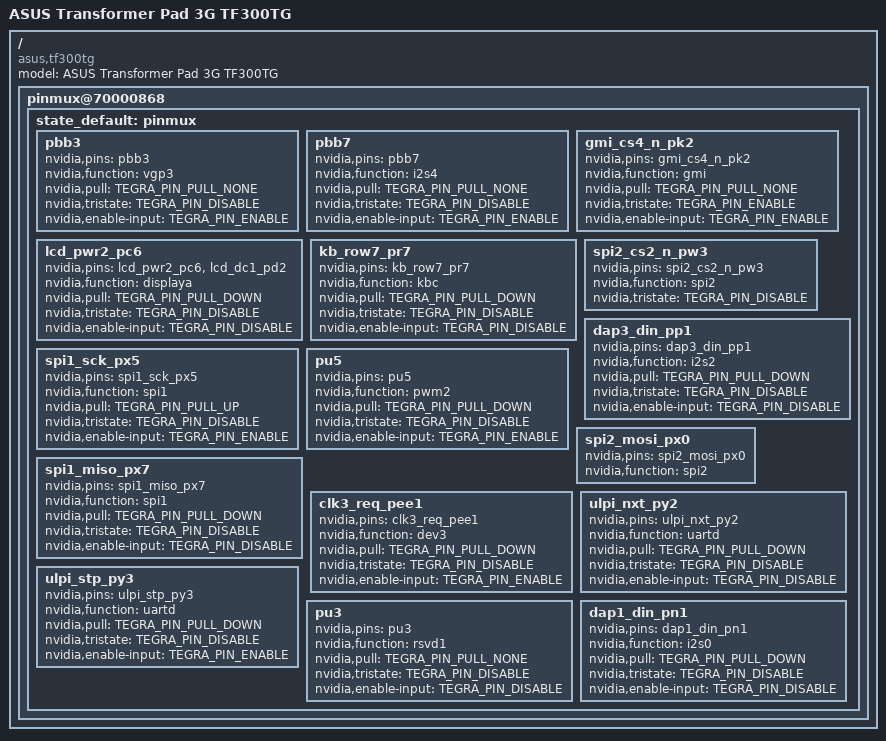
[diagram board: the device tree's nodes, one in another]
// SPDX-License-Identifier: GPL-2.0
/dts-v1/;

#include "tegra30-asus-transformer.dtsi"

/ {
	model = "ASUS Transformer Pad 3G TF300TG";
	compatible = "asus,tf300tg", "nvidia,tegra30";

	pinmux@70000868 {
		state_default: pinmux {
			pbb3 {
				nvidia,pins = "pbb3";
				nvidia,function = "vgp3";
				nvidia,pull = <TEGRA_PIN_PULL_NONE>;
				nvidia,tristate = <TEGRA_PIN_DISABLE>;
				nvidia,enable-input = <TEGRA_PIN_ENABLE>;
			};

			pbb7 {
				nvidia,pins = "pbb7";
				nvidia,function = "i2s4";
				nvidia,pull = <TEGRA_PIN_PULL_NONE>;
				nvidia,tristate = <TEGRA_PIN_DISABLE>;
				nvidia,enable-input = <TEGRA_PIN_ENABLE>;
			};

			gmi_cs4_n_pk2 {
				nvidia,pins = "gmi_cs4_n_pk2";
				nvidia,function = "gmi";
				nvidia,pull = <TEGRA_PIN_PULL_NONE>;
				nvidia,tristate = <TEGRA_PIN_ENABLE>;
				nvidia,enable-input = <TEGRA_PIN_ENABLE>;
			};

			lcd_pwr2_pc6 {
				nvidia,pins = "lcd_pwr2_pc6",
						"lcd_dc1_pd2";
				nvidia,function = "displaya";
				nvidia,pull = <TEGRA_PIN_PULL_DOWN>;
				nvidia,tristate = <TEGRA_PIN_DISABLE>;
				nvidia,enable-input = <TEGRA_PIN_DISABLE>;
			};

			kb_row7_pr7 {
				nvidia,pins = "kb_row7_pr7";
				nvidia,function = "kbc";
				nvidia,pull = <TEGRA_PIN_PULL_DOWN>;
				nvidia,tristate = <TEGRA_PIN_DISABLE>;
				nvidia,enable-input = <TEGRA_PIN_DISABLE>;
			};

			spi2_cs2_n_pw3 {
				nvidia,pins = "spi2_cs2_n_pw3";
				nvidia,function = "spi2";
				nvidia,tristate = <TEGRA_PIN_DISABLE>;
			};

			dap3_din_pp1 {
				nvidia,pins = "dap3_din_pp1";
				nvidia,function = "i2s2";
				nvidia,pull = <TEGRA_PIN_PULL_DOWN>;
				nvidia,tristate = <TEGRA_PIN_DISABLE>;
				nvidia,enable-input = <TEGRA_PIN_DISABLE>;
			};

			spi1_sck_px5 {
				nvidia,pins = "spi1_sck_px5";
				nvidia,function = "spi1";
				nvidia,pull = <TEGRA_PIN_PULL_UP>;
				nvidia,tristate = <TEGRA_PIN_DISABLE>;
				nvidia,enable-input = <TEGRA_PIN_ENABLE>;
			};

			pu5 {
				nvidia,pins = "pu5";
				nvidia,function = "pwm2";
				nvidia,pull = <TEGRA_PIN_PULL_DOWN>;
				nvidia,tristate = <TEGRA_PIN_DISABLE>;
				nvidia,enable-input = <TEGRA_PIN_ENABLE>;
			};

			spi2_mosi_px0 {
				nvidia,pins = "spi2_mosi_px0";
				nvidia,function = "spi2";
			};

			spi1_miso_px7 {
				nvidia,pins = "spi1_miso_px7";
				nvidia,function = "spi1";
				nvidia,pull = <TEGRA_PIN_PULL_DOWN>;
				nvidia,tristate = <TEGRA_PIN_DISABLE>;
				nvidia,enable-input = <TEGRA_PIN_DISABLE>;
			};

			clk3_req_pee1 {
				nvidia,pins = "clk3_req_pee1";
				nvidia,function = "dev3";
				nvidia,pull = <TEGRA_PIN_PULL_DOWN>;
				nvidia,tristate = <TEGRA_PIN_DISABLE>;
				nvidia,enable-input = <TEGRA_PIN_ENABLE>;
			};

			ulpi_nxt_py2 {
				nvidia,pins = "ulpi_nxt_py2";
				nvidia,function = "uartd";
				nvidia,pull = <TEGRA_PIN_PULL_DOWN>;
				nvidia,tristate = <TEGRA_PIN_DISABLE>;
				nvidia,enable-input = <TEGRA_PIN_DISABLE>;
			};

			ulpi_stp_py3 {
				nvidia,pins = "ulpi_stp_py3";
				nvidia,function = "uartd";
				nvidia,pull = <TEGRA_PIN_PULL_DOWN>;
				nvidia,tristate = <TEGRA_PIN_DISABLE>;
				nvidia,enable-input = <TEGRA_PIN_ENABLE>;
			};

			pu3 {
				nvidia,pins = "pu3";
				nvidia,function = "rsvd1";
				nvidia,pull = <TEGRA_PIN_PULL_NONE>;
				nvidia,tristate = <TEGRA_PIN_DISABLE>;
				nvidia,enable-input = <TEGRA_PIN_DISABLE>;
			};

			dap1_din_pn1 {
				nvidia,pins = "dap1_din_pn1";
				nvidia,function = "i2s0";
				nvidia,pull = <TEGRA_PIN_PULL_DOWN>;
				nvidia,tristate = <TEGRA_PIN_DISABLE>;
				nvidia,enable-input = <TEGRA_PIN_DISABLE>;
			};
		};
	};
};
